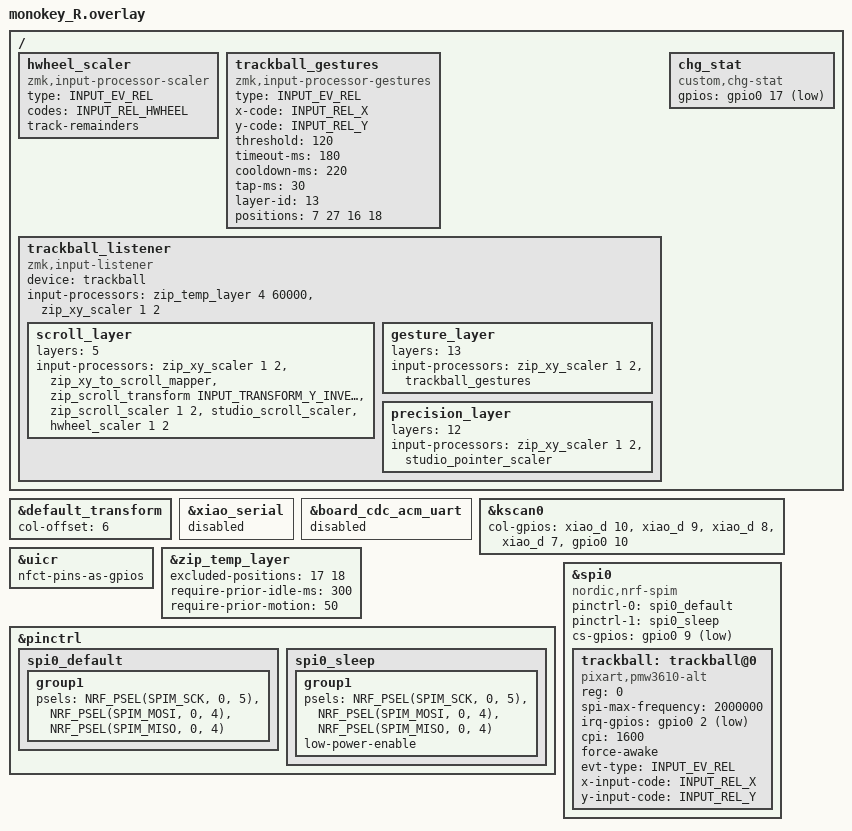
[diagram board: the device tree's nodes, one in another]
#include "monokey.dtsi"
#include <input/processors.dtsi>
#include <dt-bindings/input/input-event-codes.h>
#include <dt-bindings/zmk/input_transform.h>

&default_transform {
    col-offset = <6>;
};

&xiao_serial { status = "disabled"; };

/* Disable the xiao_ble board's default console CDC ACM so USB exposes only the
 * Studio RPC serial. boards/common/usb/cdc_acm_serial.dtsi (pulled in by
 * seeed/xiao_ble) creates board_cdc_acm_uart, which with the studio-rpc-usb-uart
 * snippet's CDC ACM made TWO "conductor" usbmodem ports (only the RPC one works).
 * Must pair with CONFIG_BOARD_SERIAL_BACKEND_CDC_ACM=n in monokey_R.conf: that
 * turns off the console backend so uart_console.c does not reference this now
 * disabled node (otherwise the non-logging build fails to link). */
&board_cdc_acm_uart { status = "disabled"; };

&kscan0 {
        col-gpios
            = <&xiao_d 10 GPIO_ACTIVE_HIGH>
            , <&xiao_d 9 GPIO_ACTIVE_HIGH> 
            , <&xiao_d 8 GPIO_ACTIVE_HIGH> 
            , <&xiao_d 7 GPIO_ACTIVE_HIGH> 
            , <&gpio0 10 GPIO_ACTIVE_HIGH>
            ;
};

/* NFC pins as GPIO (replaces CONFIG_NFCT_PINS_AS_GPIOS=y) */
&uicr {
    nfct-pins-as-gpios;
};

// 非マウスキーでAML解除
&zip_temp_layer {
    excluded-positions = <
        17 // K (MB1)
        18 // L (MB2)
    >;
    // MB-only. Shift/Ctrl/etc. are handled position-independently by the
    // temp-layer's deferred modifier check (zmk fork feature/aml-modifier-guard):
    // a held modifier keeps AML alive regardless of where it is mapped or of
    // persisted excluded-positions, so no Shift positions are needed here.
    require-prior-idle-ms = <300>;
    // タイピング後300ms経過でAMLが発動可能（100msだとsplit BLE通信ラグが顕著、750msだと反応鈍い）
    require-prior-motion = <50>;
    // モーション閾値50（元の値）: motion下げ(30)はAML発動頻度を増やしsplit BLEラグを悪化させると Codex が指摘、元に戻す
};


/ {
    /* Reduce horizontal scroll sensitivity to prevent accidental triggering */
    hwheel_scaler: hwheel_scaler {
        compatible = "zmk,input-processor-scaler";
        #input-processor-cells = <2>;
        type = <INPUT_EV_REL>;
        codes = <INPUT_REL_HWHEEL>;
        track-remainders;
    };

    trackball_gestures: trackball_gestures {
        compatible = "zmk,input-processor-gestures";
        #input-processor-cells = <0>;
        type = <INPUT_EV_REL>;
        x-code = <INPUT_REL_X>;
        y-code = <INPUT_REL_Y>;
        threshold = <120>;
        timeout-ms = <180>;
        cooldown-ms = <220>;
        tap-ms = <30>;
        layer-id = <13>;
        positions = <7 27 16 18>; /* up=I, down=COMMA, left=J, right=L */
    };

    trackball_listener {
        compatible = "zmk,input-listener";
        device = <&trackball>;

        /* ベース: オートマウスレイヤー (AML)
         * トラックボール操作時にレイヤー4 (MOUSE) を自動有効化
         * 60000ms (60秒) のタイムアウトで自動解除 */
        input-processors = <&zip_temp_layer 4 60000 &zip_xy_scaler 1 2>;

        /* スクロールレイヤー: レイヤー5 (SCROLL) がアクティブ時
         * XY移動をスクロールホイールに変換
         * スクロール速度をスケーリング (1/8) で調整 */
        scroll_layer {
            layers = <5>;
            // SMOOTH_SCROLLING: emit high-resolution wheel units. The host's
            // Resolution Multiplier divides them back to whole notches, so the
            // 1/16 down-scale that was here is removed (otherwise the value is
            // already tiny and the host divides it again -> "tiny scroll on
            // Windows"). apply_resolution_scaling (input_listener.c) does the
            // per-host /div. Net scroll amount ~unchanged; tune here if needed.
            input-processors = <&zip_xy_scaler 1 2 &zip_xy_to_scroll_mapper &zip_scroll_transform INPUT_TRANSFORM_Y_INVERT &zip_scroll_scaler 1 2 &studio_scroll_scaler &hwheel_scaler 1 2>;
        };

        gesture_layer {
            layers = <13>;
            input-processors = <&zip_xy_scaler 1 2 &trackball_gestures>;
        };

        /* 精密モード: レイヤー12 (PRECISION) がアクティブ時、
         * カーソル移動を Studio から動的に変更可能な倍率でスケールダウン。
         * 既定 1/4。Conductor Studio の Trackball タブで変更可能。
         * トグルキー（&tog 12）で ON/OFF。 */
        precision_layer {
            layers = <12>;
            input-processors = <&zip_xy_scaler 1 2 &studio_pointer_scaler>;
        };
    };

    chg_stat: chg_stat {
        compatible = "custom,chg-stat";
        /* Xiao BLE の充電検知ピン P0.17 (Low = 充電中, High = 完了/未接続) */
        gpios = <&gpio0 17 GPIO_ACTIVE_LOW>;
        status = "okay";
    };
};

&pinctrl {
    spi0_default: spi0_default {
        group1 {
            psels = <NRF_PSEL(SPIM_SCK, 0, 5)>,
                <NRF_PSEL(SPIM_MOSI, 0, 4)>,
                <NRF_PSEL(SPIM_MISO, 0, 4)>;
        };
    };

    spi0_sleep: spi0_sleep {
        group1 {
            psels = <NRF_PSEL(SPIM_SCK, 0, 5)>,
                <NRF_PSEL(SPIM_MOSI, 0, 4)>,
                <NRF_PSEL(SPIM_MISO, 0, 4)>;
            low-power-enable;
        };
    };
};

&spi0 {
    status = "okay";
    compatible = "nordic,nrf-spim";
    pinctrl-0 = <&spi0_default>;
    pinctrl-1 = <&spi0_sleep>;
    pinctrl-names = "default", "sleep";
    cs-gpios = <&gpio0 9 GPIO_ACTIVE_LOW>;

    trackball: trackball@0 {
        status = "okay";
        compatible = "pixart,pmw3610-alt";
        reg = <0>;
        spi-max-frequency = <2000000>;
        irq-gpios = <&gpio0 2 (GPIO_ACTIVE_LOW | GPIO_PULL_UP)>;
        cpi = <1600>;
        force-awake;
        evt-type = <INPUT_EV_REL>;
        x-input-code = <INPUT_REL_X>;
        y-input-code = <INPUT_REL_Y>;
    };
};
